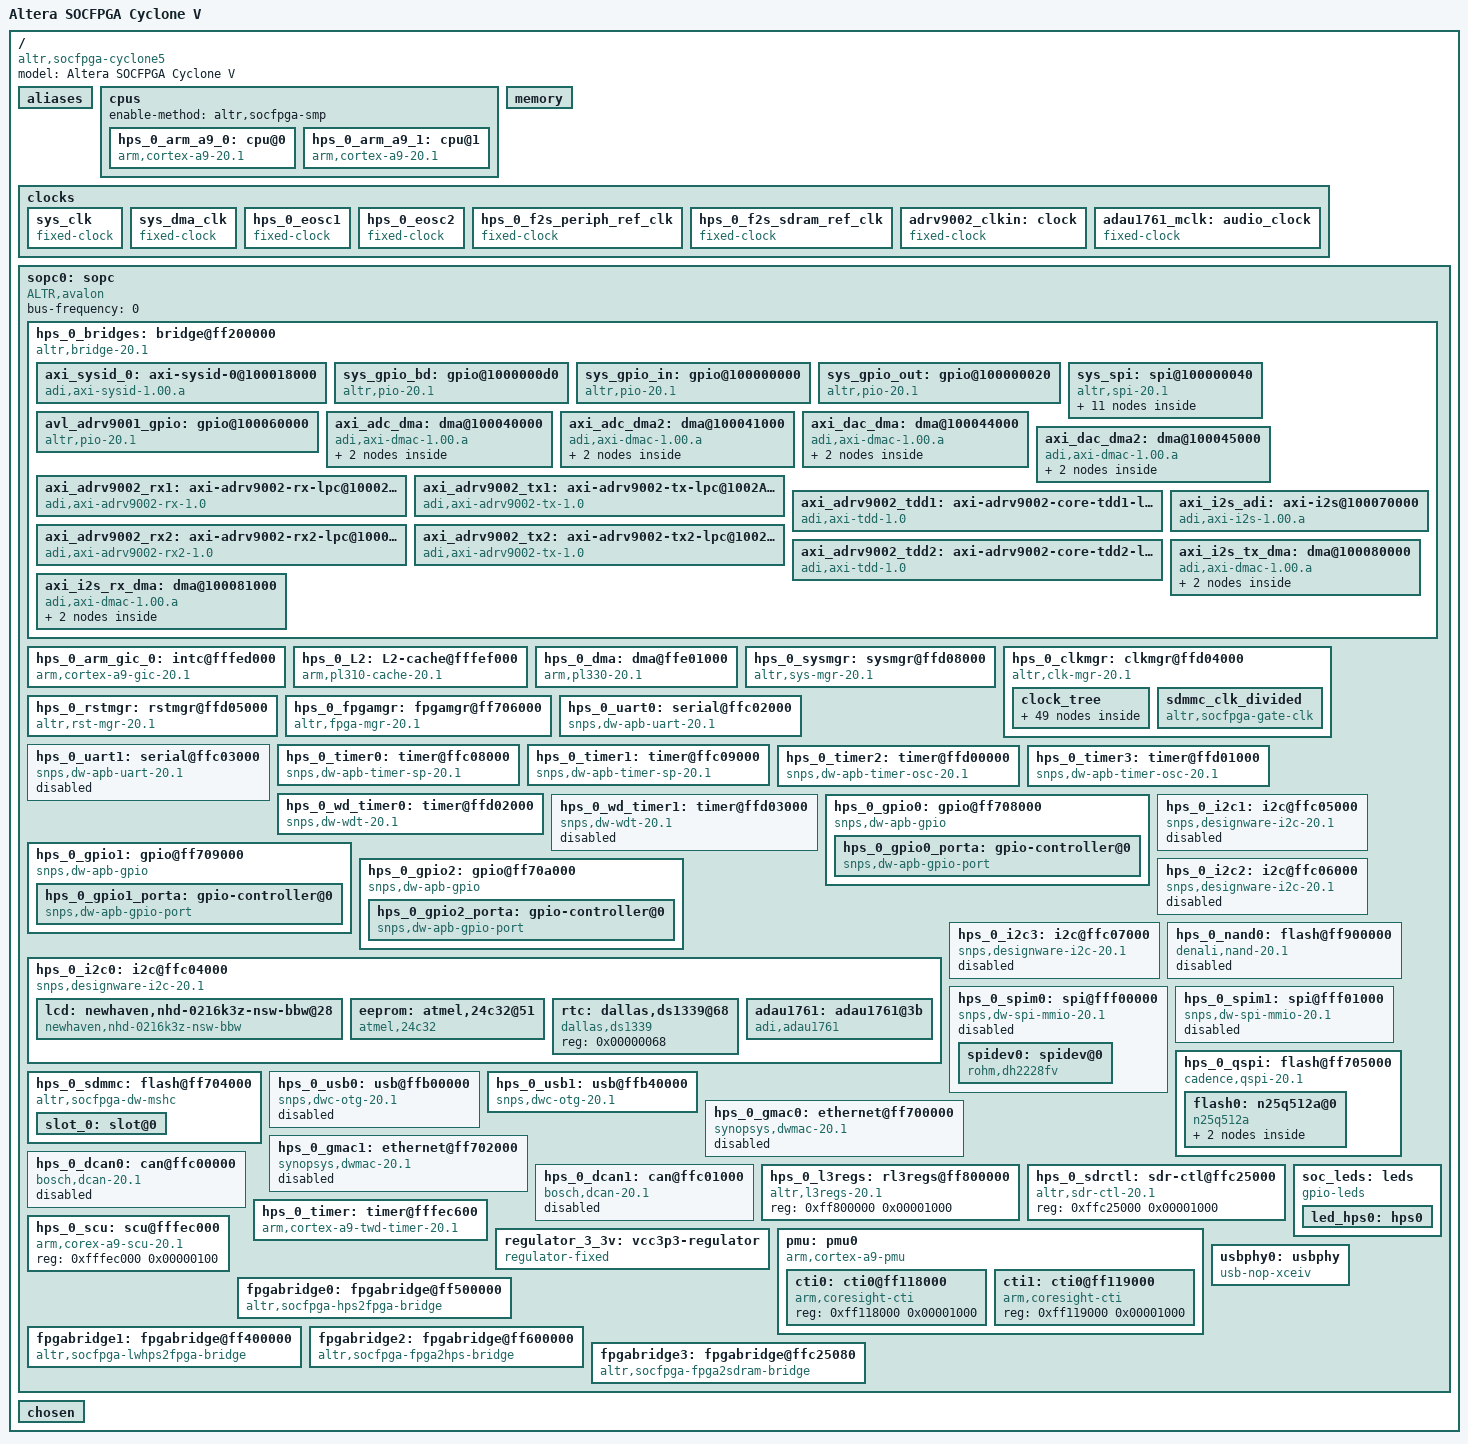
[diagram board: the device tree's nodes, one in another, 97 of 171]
/*
 * This devicetree is generated by sopc2dts version 20.1 [9b3346002ac555f36b80b1bc56dad1cb86298234] on Fri Sep 02 09:02:25 JST 2022
 * Sopc2dts is written by Walter Goossens <waltergoossens@home.nl>
 * in cooperation with the nios2 community <nios2-dev@lists.rocketboards.org>
 */
/dts-v1/;

/ {
	model = "Altera SOCFPGA Cyclone V";	/* appended from boardinfo */
	compatible = "altr,socfpga-cyclone5", "altr,socfpga";	/* appended from boardinfo */
	#address-cells = <1>;
	#size-cells = <1>;

	aliases {
		ethernet0 = "/sopc/ethernet@ff702000";
		serial0 = &hps_0_uart0;
		serial1 = &hps_0_uart1;
	}; //end aliases

	cpus {
		#address-cells = <1>;
		#size-cells = <0>;
		enable-method = "altr,socfpga-smp";	/* appended from boardinfo */

		hps_0_arm_a9_0: cpu@0 {
			device_type = "cpu";
			compatible = "arm,cortex-a9-20.1", "arm,cortex-a9";
			reg = <0x00000000>;
			next-level-cache = <&hps_0_L2>;	/* appended from boardinfo */
		}; //end cpu@0 (hps_0_arm_a9_0)

		hps_0_arm_a9_1: cpu@1 {
			device_type = "cpu";
			compatible = "arm,cortex-a9-20.1", "arm,cortex-a9";
			reg = <0x00000001>;
			next-level-cache = <&hps_0_L2>;	/* appended from boardinfo */
		}; //end cpu@1 (hps_0_arm_a9_1)
	}; //end cpus

	memory {
		device_type = "memory";
		reg = <0xffff0000 0x00010000>,
			<0x00000000 0x80000000>;
	}; //end memory

	clocks {
		#address-cells = <1>;
		#size-cells = <1>;

		sys_clk: sys_clk {
			compatible = "fixed-clock";
			#clock-cells = <0>;
			clock-frequency = <50000000>;	/* 50.00 MHz */
			clock-output-names = "sys_clk-clk";
		}; //end sys_clk (sys_clk)

		sys_dma_clk: sys_dma_clk {
			compatible = "fixed-clock";
			#clock-cells = <0>;
			clock-frequency = <80000000>;	/* 80.00 MHz */
			clock-output-names = "sys_dma_clk-clk";
		}; //end sys_dma_clk (sys_dma_clk)

		hps_0_eosc1: hps_0_eosc1 {
			compatible = "fixed-clock";
			#clock-cells = <0>;
			clock-frequency = <25000000>;	/* 25.00 MHz */
			clock-output-names = "hps_0_eosc1-clk";
		}; //end hps_0_eosc1 (hps_0_eosc1)

		hps_0_eosc2: hps_0_eosc2 {
			compatible = "fixed-clock";
			#clock-cells = <0>;
			clock-frequency = <25000000>;	/* 25.00 MHz */
			clock-output-names = "hps_0_eosc2-clk";
		}; //end hps_0_eosc2 (hps_0_eosc2)

		hps_0_f2s_periph_ref_clk: hps_0_f2s_periph_ref_clk {
			compatible = "fixed-clock";
			#clock-cells = <0>;
			clock-frequency = <0>;	/* 0.00 Hz */
			clock-output-names = "hps_0_f2s_periph_ref_clk-clk";
		}; //end hps_0_f2s_periph_ref_clk (hps_0_f2s_periph_ref_clk)

		hps_0_f2s_sdram_ref_clk: hps_0_f2s_sdram_ref_clk {
			compatible = "fixed-clock";
			#clock-cells = <0>;
			clock-frequency = <0>;	/* 0.00 Hz */
			clock-output-names = "hps_0_f2s_sdram_ref_clk-clk";
		}; //end hps_0_f2s_sdram_ref_clk (hps_0_f2s_sdram_ref_clk)

		adrv9002_clkin: clock {
			compatible = "fixed-clock";
			clock-frequency = <49152000>;
			clock-output-names = "adrv9002_ext_refclk";
			#clock-cells = <0>;
		};

		adau1761_mclk: audio_clock {
			compatible = "fixed-clock";
			#clock-cells=<0>;
			clock-frequency = <12288000>;
			clock-output-names = "adau1761_mclk";
		};
	}; //end clocks

	sopc0: sopc {
		device_type = "soc";
		ranges;
		#address-cells = <1>;
		#size-cells = <1>;
		compatible = "ALTR,avalon", "simple-bus";
		bus-frequency = <0>;

		hps_0_bridges: bridge@ff200000 {
			compatible = "altr,bridge-20.1", "simple-bus";
			reg = <0xff200000 0x00200000>;
			clocks = <&sys_clk &sys_dma_clk>;
			clock-names = "h2f_lw_axi_clock", "f2h_sdram0_clock";
			#address-cells = <2>;
			#size-cells = <1>;
			ranges = <0x00000001 0x000000d0 0xff2000d0 0x00000010>,
				<0x00000001 0x00000000 0xff200000 0x00000010>,
				<0x00000001 0x00000020 0xff200020 0x00000010>,
				<0x00000001 0x00060000 0xff260000 0x00000010>,
				<0x00000001 0x00020000 0xff220000 0x00010000>,
				<0x00000001 0x00040000 0xff240000 0x00000800>,
				<0x00000001 0x00044000 0xff244000 0x00000800>,
				<0x00000001 0x00018000 0xff218000 0x00008000>,
				<0x00000001 0x00041000 0xff241000 0x00000800>,
				<0x00000001 0x00045000 0xff245000 0x00000800>,
				<0x00000001 0x00070000 0xff270000 0x00010000>,
				<0x00000001 0x00080000 0xff280000 0x00000800>,
				<0x00000001 0x00081000 0xff281000 0x00000800>,
				<0x00000001 0x00000040 0xff200040 0x00000020>;

			axi_sysid_0: axi-sysid-0@100018000 {
				compatible = "adi,axi-sysid-1.00.a";
				reg = <0x00000001 0x00018000 0x00008000>;
				clocks = <&sys_clk>;
			}; //end axi-sysid-0@100018000 (axi_sysid_0)

			sys_gpio_bd: gpio@1000000d0 {
				compatible = "altr,pio-20.1", "altr,pio-1.0";
				reg = <0x00000001 0x000000d0 0x00000010>;
				interrupt-parent = <&hps_0_arm_gic_0>;
				interrupts = <0 48 4>;
				clocks = <&sys_clk>;
				altr,gpio-bank-width = <32>;	/* embeddedsw.dts.params.altr,gpio-bank-width type NUMBER */
				altr,interrupt-type = <4>;	/* embeddedsw.dts.params.altr,interrupt-type type NUMBER */
				altr,interrupt_type = <4>;	/* embeddedsw.dts.params.altr,interrupt_type type NUMBER */
				level_trigger = <1>;	/* embeddedsw.dts.params.level_trigger type NUMBER */
				resetvalue = <0>;	/* embeddedsw.dts.params.resetvalue type NUMBER */
				#gpio-cells = <2>;
				gpio-controller;
			}; //end gpio@1000000d0 (sys_gpio_bd)

			sys_gpio_in: gpio@100000000 {
				compatible = "altr,pio-20.1", "altr,pio-1.0";
				reg = <0x00000001 0x00000000 0x00000010>;
				interrupt-parent = <&hps_0_arm_gic_0>;
				interrupts = <0 49 4>;
				clocks = <&sys_clk>;
				altr,gpio-bank-width = <32>;	/* embeddedsw.dts.params.altr,gpio-bank-width type NUMBER */
				altr,interrupt-type = <4>;	/* embeddedsw.dts.params.altr,interrupt-type type NUMBER */
				altr,interrupt_type = <4>;	/* embeddedsw.dts.params.altr,interrupt_type type NUMBER */
				level_trigger = <1>;	/* embeddedsw.dts.params.level_trigger type NUMBER */
				resetvalue = <0>;	/* embeddedsw.dts.params.resetvalue type NUMBER */
				#gpio-cells = <2>;
				gpio-controller;
			}; //end gpio@100000000 (sys_gpio_in)

			sys_gpio_out: gpio@100000020 {
				compatible = "altr,pio-20.1", "altr,pio-1.0";
				reg = <0x00000001 0x00000020 0x00000010>;
				clocks = <&sys_clk>;
				altr,gpio-bank-width = <32>;	/* embeddedsw.dts.params.altr,gpio-bank-width type NUMBER */
				resetvalue = <0>;	/* embeddedsw.dts.params.resetvalue type NUMBER */
				#gpio-cells = <2>;
				gpio-controller;
			}; //end gpio@100000020 (sys_gpio_out)

			sys_spi: spi@100000040 {
				compatible = "altr,spi-20.1", "altr,spi-1.0";
				reg = <0x00000001 0x00000040 0x00000020>;
				interrupt-parent = <&hps_0_arm_gic_0>;
				interrupts = <0 46 4>;
				clocks = <&sys_clk>;
				#address-cells = <1>;
				#size-cells = <0>;
				bus-num = <0>;
				num-chipselect = <1>;
				status = "okay";

				adc0_adrv9002: adrv9002-phy@0 {
					compatible = "adi,adrv9002";
					reg = <0x0>;
					spi-max-frequency = <10000000>;
					clocks = <&adrv9002_clkin 0x0>;
					clock-names = "adrv9002_ext_refclk";
					clock-output-names = "rx1_sampl_clk", "tx1_sampl_clk", "tdd1_intf_clk", "rx2_sampl_clk", "tx2_sampl_clk", "tdd2_intf_clk";
					#clock-cells = <0x1>;
					interrupt-parent = <&avl_adrv9001_gpio>;
					reset-gpios = <&avl_adrv9001_gpio 14 1>;
					ssi-sync-gpios = <&avl_adrv9001_gpio 20 0>;

					adi,channels {
						#address-cells = <1>;
						#size-cells = <0>;

						rx0: rx@0 {
							reg = <0>;
							adi,port = <0>;
							orx-gpios = <&avl_adrv9001_gpio 0 0>; /* dgpio0 */
						};

						rx1: rx@1 {
							reg = <1>;
							adi,port = <0>;
							orx-gpios = <&avl_adrv9001_gpio 1 0>; /* dgpio1 */
						};

						tx0: tx@0 {
							reg = <0>;
							adi,port = <1>;
						};

						tx1: tx@1 {
							reg = <1>;
							adi,port = <1>;
						};

					};

					adi,gpios {
						#address-cells = <1>;
						#size-cells = <0>;

						gpio@0 {
							reg = <1>;
							adi,signal = <0>; /* ADI_ADRV9001_GPIO_SIGNAL_ORX_ENABLE_1 */
						};

						gpio@1 {
							reg = <2>;
							adi,signal = <1>; /* ADI_ADRV9001_GPIO_SIGNAL_ORX_ENABLE_2 */
						};
					};

					adi,frequency-hopping {
						adi,fh-mode = <0x3>;
						adi-fh-rx-zero-if-en;

						adi,fh-hop-signal-2 {
							adi,fh-hop-rx-ports = <0x1>;
							adi,fh-hop-tx-ports = <0x1>;
						};
					};
				};
			}; //end spi@100000040 (sys_spi)

			avl_adrv9001_gpio: gpio@100060000 {
				compatible = "altr,pio-20.1", "altr,pio-1.0";
				reg = <0x00000001 0x00060000 0x00000010>;
				interrupt-parent = <&hps_0_arm_gic_0>;
				interrupts = <0 47 4>;
				clocks = <&sys_clk>;
				altr,gpio-bank-width = <19>;	/* embeddedsw.dts.params.altr,gpio-bank-width type NUMBER */
				altr,interrupt-type = <4>;	/* embeddedsw.dts.params.altr,interrupt-type type NUMBER */
				altr,interrupt_type = <4>;	/* embeddedsw.dts.params.altr,interrupt_type type NUMBER */
				level_trigger = <1>;	/* embeddedsw.dts.params.level_trigger type NUMBER */
				resetvalue = <0>;	/* embeddedsw.dts.params.resetvalue type NUMBER */
				#gpio-cells = <2>;
				gpio-controller;
			}; //end gpio@100060000 (avl_adrv9001_gpio)

			axi_adc_dma: dma@100040000 {
				compatible = "adi,axi-dmac-1.00.a";
				reg = <0x00000001 0x00040000 0x00000800>;
				#dma-cells = <0x1>;
				interrupt-parent = <&hps_0_arm_gic_0>;
				interrupts = <0 40 4>;
				clocks = <&sys_clk &sys_dma_clk &sys_dma_clk>;
				clock-names = "s_axi_clock", "m_dest_axi_clock", "if_fifo_wr_clk";
				adi,channels {
					#size-cells = <0>;
					#address-cells = <1>;

					dma-channel@0 {
						reg = <0>;
						adi,source-bus-width = <64>;
						adi,source-bus-type = <2>;
						adi,destination-bus-width = <64>;
						adi,destination-bus-type = <0>;
					};
				};
			}; //end dma@100040000 (axi_adc_dma)

			axi_adc_dma2: dma@100041000 {
				compatible = "adi,axi-dmac-1.00.a";
				reg = <0x00000001 0x00041000 0x00000800>;
				#dma-cells = <0x1>;
				interrupt-parent = <&hps_0_arm_gic_0>;
				interrupts = <0 41 4>;
				clocks = <&sys_clk &sys_dma_clk &sys_dma_clk>;
				clock-names = "s_axi_clock", "m_dest_axi_clock", "if_fifo_wr_clk";
				adi,channels {
					#size-cells = <0>;
					#address-cells = <1>;

					dma-channel@0 {
						reg = <0>;
						adi,source-bus-width = <64>;
						adi,source-bus-type = <2>;
						adi,destination-bus-width = <64>;
						adi,destination-bus-type = <0>;
					};
				};
			}; //end dma@100041000 (axi_adc_dma2)

			axi_dac_dma: dma@100044000 {
				compatible = "adi,axi-dmac-1.00.a";
				reg = <0x00000001 0x00044000 0x00000800>;
				#dma-cells = <0x1>;
				interrupt-parent = <&hps_0_arm_gic_0>;
				interrupts = <0 42 4>;
				clocks = <&sys_clk &sys_dma_clk &sys_dma_clk>;
				clock-names = "s_axi_clock", "m_src_axi_clock", "if_m_axis_aclk";
				adi,channels {
					#size-cells = <0>;
					#address-cells = <1>;
					dma-channel@0 {
						reg = <0>;
						adi,source-bus-width = <64>;
						adi,source-bus-type = <0>;
						adi,destination-bus-width = <64>;
						adi,destination-bus-type = <2>;
					};
				};
			}; //end dma@100044000 (axi_dac_dma)

			axi_dac_dma2: dma@100045000 {
				compatible = "adi,axi-dmac-1.00.a";
				reg = <0x00000001 0x00045000 0x00000800>;
				#dma-cells = <0x1>;
				interrupt-parent = <&hps_0_arm_gic_0>;
				interrupts = <0 43 4>;
				clocks = <&sys_clk &sys_dma_clk &sys_dma_clk>;
				clock-names = "s_axi_clock", "m_src_axi_clock", "if_m_axis_aclk";
				adi,channels {
					#size-cells = <0>;
					#address-cells = <1>;
					dma-channel@0 {
						reg = <0>;
						adi,source-bus-width = <64>;
						adi,source-bus-type = <0>;
						adi,destination-bus-width = <64>;
						adi,destination-bus-type = <2>;
					};
				};
			}; //end dma@100045000 (axi_dac_dma2)

			axi_adrv9002_rx1: axi-adrv9002-rx-lpc@100020000 {
				compatible = "adi,axi-adrv9002-rx-1.0";
				reg = <0x00000001 0x00020000 0x00006000>;
				clocks = <&adc0_adrv9002 0>;
				dmas = <&axi_adc_dma 0>;
				dma-names = "rx";
				spibus-connected = <&adc0_adrv9002>;
			}; //end axi-adrv9002-rx-lpc@100020000 (axi_adrv9002_rx1)

			axi_adrv9002_tx1: axi-adrv9002-tx-lpc@1002A000 {
				compatible = "adi,axi-adrv9002-tx-1.0";
				reg = <0x00000001 0x0002A000 0x00002000>;
				clocks = <&adc0_adrv9002 1>;
				clock-names = "sampl_clk";
				dmas = <&axi_dac_dma 0>;
				dma-names = "tx";
				adi,axi-dds-default-scale = <0x800>;
				adi,axi-dds-default-frequency = <2000000>;
			}; //end axi-adrv9002-tx-lpc@1003A000 (axi_adrv9002_tx1)

			axi_adrv9002_tdd1: axi-adrv9002-core-tdd1-lpc@1002C800 {
				compatible = "adi,axi-tdd-1.0";
				reg = <0x00000001 0x0002C800 0x00000400>;
				clocks = <&sys_dma_clk>, <&adc0_adrv9002 2>;
				clock-names = "s_axi_aclk", "intf_clk";
				label = "axi-core-tdd-1";
			}; //end axi-adrv9002-core-tdd1-lpc@1002C800 (axi_adrv9002_tdd1)

			axi_adrv9002_rx2: axi-adrv9002-rx2-lpc@100029000 {
				compatible = "adi,axi-adrv9002-rx2-1.0";
				reg = <0x00000001 0x00029000 0x00001000>;
				clocks = <&adc0_adrv9002 3>;
				clock-names = "sampl_clk";
				dmas = <&axi_adc_dma2 0>;
				dma-names = "rx";
			}; //end axi-adrv9002-rx-lpc@100029000 (axi_adrv9002_rx2)

			axi_adrv9002_tx2: axi-adrv9002-tx2-lpc@1002C000 {
				compatible = "adi,axi-adrv9002-tx-1.0";
				reg = <0x00000001 0x0002C000 0x00002000>;
				clocks = <&adc0_adrv9002 4>;
				clock-names = "sampl_clk";
				dmas = <&axi_dac_dma2 0>;
				dma-names = "tx";
				adi,axi-dds-default-scale = <0x800>;
				adi,axi-dds-default-frequency = <2000000>;
			}; //end axi-adrv9002-tx2-lpc@1002C000 (axi_adrv9002_tx2)

			axi_adrv9002_tdd2: axi-adrv9002-core-tdd2-lpc@1002CC00 {
				compatible = "adi,axi-tdd-1.0";
				reg = <0x00000001 0x0002CC00 0x00000400>;
				clocks = <&sys_dma_clk>, <&adc0_adrv9002 5>;
				clock-names = "s_axi_aclk", "intf_clk";
				label = "axi-core-tdd-2";
			}; //end axi-adrv9002-core-tdd2-lpc@1002CC00 (axi_adrv9002_tdd2)

			axi_i2s_adi: axi-i2s@100070000 {
				compatible = "adi,axi-i2s-1.00.a";
				reg = <0x00000001 0x00070000 0x00010000>;
				clocks = <&sys_clk &adau1761_mclk>; // clocks = <&sys_clk &sys_clk &sys_clk>;
				clock-names = "axi", "ref"; // clock-names = "s_axi_clock", "if_m_axis_aclk", "if_s_axis_aclk";
				dmas = <&axi_i2s_tx_dma 0 &axi_i2s_rx_dma 0>; // dmas = <&axi_i2s_tx_dma 0 &axi_i2s_rx_dma 1>;
				dma-names = "tx", "rx"; 
			}; //end axi-i2s@100070000 (axi_i2s_adi)

			axi_i2s_tx_dma: dma@100080000 {
				compatible = "adi,axi-dmac-1.00.a";
				reg = <0x00000001 0x00080000 0x00000800>;
				#dma-cells = <0x1>; // #dma-cells = <0x2>;
				interrupt-parent = <&hps_0_arm_gic_0>;
				interrupts = <0 44 4>;
				clocks = <&sys_clk &sys_clk &sys_clk>;
				clock-names = "s_axi_clock", "m_src_axi_clock", "if_m_axis_aclk";
				adi,channels {
					#size-cells = <0>;
					#address-cells = <1>;
					dma-channel@0 {
						reg = <0>;
						adi,source-bus-width = <64>;
						adi,source-bus-type = <0>;
						adi,destination-bus-width = <32>;
						adi,destination-bus-type = <1>;
					};
				};
			}; //end dma@100080000 (axi_i2s_tx_dma)

			axi_i2s_rx_dma: dma@100081000 {
				compatible = "adi,axi-dmac-1.00.a";
				reg = <0x00000001 0x00081000 0x00000800>;
				#dma-cells = <0x1>; // #dma-cells = <0x3>;
				interrupt-parent = <&hps_0_arm_gic_0>;
				interrupts = <0 45 4>;
				clocks = <&sys_clk &sys_clk &sys_clk>;
				clock-names = "s_axi_clock", "m_dest_axi_clock", "if_s_axis_aclk";
				adi,channels {
					#size-cells = <0>;
					#address-cells = <1>;
					dma-channel@0 {
						reg = <0>;
						adi,source-bus-width = <32>;
						adi,source-bus-type = <1>;
						adi,destination-bus-width = <64>;
						adi,destination-bus-type = <0>;
					};
				};
			}; //end dma@100081000 (axi_i2s_rx_dma)

		}; //end bridge@ff200000 (hps_0_bridges)

		hps_0_arm_gic_0: intc@fffed000 {
			compatible = "arm,cortex-a9-gic-20.1", "arm,cortex-a9-gic";
			reg = <0xfffed000 0x00001000>,
				<0xfffec100 0x00000100>;
			reg-names = "axi_slave0", "axi_slave1";
			interrupt-controller;
			#interrupt-cells = <3>;
		}; //end intc@fffed000 (hps_0_arm_gic_0)

		hps_0_L2: L2-cache@fffef000 {
			compatible = "arm,pl310-cache-20.1", "arm,pl310-cache";
			reg = <0xfffef000 0x00001000>;
			interrupt-parent = <&hps_0_arm_gic_0>;
			interrupts = <0 38 4>;
			cache-level = <2>;	/* embeddedsw.dts.params.cache-level type NUMBER */
			cache-unified;	/* appended from boardinfo */
			arm,tag-latency = <1 1 1>;	/* appended from boardinfo */
			arm,data-latency = <2 1 1>;	/* appended from boardinfo */
		}; //end L2-cache@fffef000 (hps_0_L2)

		hps_0_dma: dma@ffe01000 {
			compatible = "arm,pl330-20.1", "arm,pl330", "arm,primecell";
			reg = <0xffe01000 0x00001000>;
			interrupt-parent = <&hps_0_arm_gic_0>;
			interrupts = <0 104 4>;
			clocks = <&l4_main_clk>;
			#dma-cells = <1>;	/* embeddedsw.dts.params.#dma-cells type NUMBER */
			#dma-channels = <8>;	/* embeddedsw.dts.params.#dma-channels type NUMBER */
			#dma-requests = <32>;	/* embeddedsw.dts.params.#dma-requests type NUMBER */
			clock-names = "apb_pclk";	/* embeddedsw.dts.params.clock-names type STRING */
			copy-align = <3>;	/* embeddedsw.dts.params.copy-align type NUMBER */
			nr-irqs = <9>;	/* embeddedsw.dts.params.nr-irqs type NUMBER */
			nr-valid-peri = <9>;	/* embeddedsw.dts.params.nr-valid-peri type NUMBER */
		}; //end dma@ffe01000 (hps_0_dma)

		hps_0_sysmgr: sysmgr@ffd08000 {
			compatible = "altr,sys-mgr-20.1", "altr,sys-mgr", "syscon";
			reg = <0xffd08000 0x00000400>;
			cpu1-start-addr = <4291854532>;	/* embeddedsw.dts.params.cpu1-start-addr type NUMBER */
		}; //end sysmgr@ffd08000 (hps_0_sysmgr)

		hps_0_clkmgr: clkmgr@ffd04000 {
			compatible = "altr,clk-mgr-20.1", "altr,clk-mgr";
			reg = <0xffd04000 0x00001000>;
			clocks = <&hps_0_eosc1 &hps_0_eosc2 &hps_0_f2s_periph_ref_clk &hps_0_f2s_sdram_ref_clk>;
			clock-names = "eosc1", "eosc2", "f2s_periph_ref_clk", "f2s_sdram_ref_clk";

			clock_tree {
				#size-cells = <0>;
				#address-cells = <1>;

				sdram_pll: sdram_pll@c0 {
					compatible = "altr,socfpga-pll-clock";
					reg = <0x000000c0>;
					clocks = <&hps_0_eosc1 &hps_0_eosc2 &hps_0_f2s_sdram_ref_clk>;
					clock-names = "hps_0_eosc1", "hps_0_eosc2", "hps_0_f2s_sdram_ref_clk";
					#clock-cells = <0>;
					#address-cells = <1>;
					#size-cells = <0>;

					ddr_dqs_clk: ddr_dqs_clk@c8 {
						compatible = "altr,socfpga-perip-clk";
						reg = <0x000000c8>;
						clocks = <&sdram_pll>;
						#clock-cells = <0>;
					}; //end ddr_dqs_clk (ddr_dqs_clk)

					ddr_2x_dqs_clk: ddr_2x_dqs_clk@cc {
						compatible = "altr,socfpga-perip-clk";
						reg = <0x000000cc>;
						clocks = <&sdram_pll>;
						#clock-cells = <0>;
					}; //end ddr_2x_dqs_clk (ddr_2x_dqs_clk)

					ddr_dq_clk: ddr_dq_clk@d0 {
						compatible = "altr,socfpga-perip-clk";
						reg = <0x000000d0>;
						clocks = <&sdram_pll>;
						#clock-cells = <0>;
					}; //end ddr_dq_clk (ddr_dq_clk)

					s2f_usr2_clk: s2f_usr2_clk@d4 {
						compatible = "altr,socfpga-perip-clk";
						reg = <0x000000d4>;
						clocks = <&sdram_pll>;
						#clock-cells = <0>;
					}; //end s2f_usr2_clk (s2f_usr2_clk)
				}; //end sdram_pll (sdram_pll)

				periph_pll: periph_pll@80 {
					compatible = "altr,socfpga-pll-clock";
					reg = <0x00000080>;
					clocks = <&hps_0_eosc1 &hps_0_eosc2 &hps_0_f2s_periph_ref_clk>;
					clock-names = "hps_0_eosc1", "hps_0_eosc2", "hps_0_f2s_periph_ref_clk";
					#clock-cells = <0>;
					#address-cells = <1>;
					#size-cells = <0>;

					per_nand_mmc_clk: per_nand_mmc_clk@94 {
						compatible = "altr,socfpga-perip-clk";
						reg = <0x00000094>;
						clocks = <&periph_pll>;
						#clock-cells = <0>;
					}; //end per_nand_mmc_clk (per_nand_mmc_clk)

					per_base_clk: per_base_clk@98 {
						compatible = "altr,socfpga-perip-clk";
						reg = <0x00000098>;
						clocks = <&periph_pll>;
						#clock-cells = <0>;
					}; //end per_base_clk (per_base_clk)

					per_qspi_clk: per_qspi_clk@90 {
						compatible = "altr,socfpga-perip-clk";
						reg = <0x00000090>;
						clocks = <&periph_pll>;
						#clock-cells = <0>;
					}; //end per_qspi_clk (per_qspi_clk)

					s2f_usr1_clk: s2f_usr1_clk@9c {
						compatible = "altr,socfpga-perip-clk";
						reg = <0x0000009c>;
						clocks = <&periph_pll>;
						#clock-cells = <0>;
					}; //end s2f_usr1_clk (s2f_usr1_clk)

					emac0_clk: emac0_clk@88 {
						compatible = "altr,socfpga-perip-clk";
						reg = <0x00000088>;
						clocks = <&periph_pll>;
						#clock-cells = <0>;
					}; //end emac0_clk (emac0_clk)

					emac1_clk: emac1_clk@8c {
						compatible = "altr,socfpga-perip-clk";
						reg = <0x0000008c>;
						clocks = <&periph_pll>;
						#clock-cells = <0>;
					}; //end emac1_clk (emac1_clk)
				}; //end periph_pll (periph_pll)

				main_pll: main_pll@40 {
					compatible = "altr,socfpga-pll-clock";
					reg = <0x00000040>;
					clocks = <&hps_0_eosc1>;
					#clock-cells = <0>;
					#address-cells = <1>;
					#size-cells = <0>;

					cfg_s2f_usr0_clk: cfg_s2f_usr0_clk@5c {
						compatible = "altr,socfpga-perip-clk";
						reg = <0x0000005c>;
						clocks = <&main_pll>;
						#clock-cells = <0>;
					}; //end cfg_s2f_usr0_clk (cfg_s2f_usr0_clk)

					main_qspi_clk: main_qspi_clk@54 {
						compatible = "altr,socfpga-perip-clk";
						reg = <0x00000054>;
						clocks = <&main_pll>;
						#clock-cells = <0>;
					}; //end main_qspi_clk (main_qspi_clk)

					dbg_base_clk: dbg_base_clk@50 {
						compatible = "altr,socfpga-perip-clk";
						reg = <0x00000050>;
						clocks = <&main_pll &hps_0_eosc1>;
						clock-names = "main_pll", "hps_0_eosc1";
						#clock-cells = <0>;
						div-reg = <0x000000e8 0x00000000 0x00000009>;
					}; //end dbg_base_clk (dbg_base_clk)

					mpuclk: mpuclk@48 {
						compatible = "altr,socfpga-perip-clk";
						reg = <0x00000048>;
						clocks = <&main_pll>;
						#clock-cells = <0>;
						div-reg = <0x000000e0 0x00000000 0x00000009>;
					}; //end mpuclk (mpuclk)

					mainclk: mainclk@4c {
						compatible = "altr,socfpga-perip-clk";
						reg = <0x0000004c>;
						clocks = <&main_pll>;
						#clock-cells = <0>;
						div-reg = <0x000000e4 0x00000000 0x00000009>;
					}; //end mainclk (mainclk)

					main_nand_sdmmc_clk: main_nand_sdmmc_clk@58 {
						compatible = "altr,socfpga-perip-clk";
						reg = <0x00000058>;
						clocks = <&main_pll>;
						#clock-cells = <0>;
					}; //end main_nand_sdmmc_clk (main_nand_sdmmc_clk)
				}; //end main_pll (main_pll)

				mpu_l2_ram_clk: mpu_l2_ram_clk {
					compatible = "altr,socfpga-gate-clk";
					clocks = <&mpuclk>;
					#clock-cells = <0>;
					fixed-divider = <2>;
				}; //end mpu_l2_ram_clk (mpu_l2_ram_clk)

				l4_main_clk: l4_main_clk {
					compatible = "altr,socfpga-gate-clk";
					clocks = <&mainclk>;
					#clock-cells = <0>;
					clk-gate = <0x00000060 0x00000000>;
				}; //end l4_main_clk (l4_main_clk)

				l3_mp_clk: l3_mp_clk {
					compatible = "altr,socfpga-gate-clk";
					clocks = <&mainclk>;
					#clock-cells = <0>;
					clk-gate = <0x00000060 0x00000001>;
					div-reg = <0x00000064 0x00000000 0x00000002>;
				}; //end l3_mp_clk (l3_mp_clk)

				l3_sp_clk: l3_sp_clk {
					compatible = "altr,socfpga-gate-clk";
					clocks = <&l3_mp_clk>;
					#clock-cells = <0>;
					div-reg = <0x00000064 0x00000002 0x00000002>;
				}; //end l3_sp_clk (l3_sp_clk)

				l4_mp_clk: l4_mp_clk {
					compatible = "altr,socfpga-gate-clk";
					clocks = <&mainclk &per_base_clk>;
					clock-names = "mainclk", "per_base_clk";
					#clock-cells = <0>;
					clk-gate = <0x00000060 0x00000002>;
					div-reg = <0x00000064 0x00000004 0x00000003>;
				}; //end l4_mp_clk (l4_mp_clk)

				l4_sp_clk: l4_sp_clk {
					compatible = "altr,socfpga-gate-clk";
					clocks = <&mainclk &per_base_clk>;
					clock-names = "mainclk", "per_base_clk";
					#clock-cells = <0>;
					clk-gate = <0x00000060 0x00000003>;
					div-reg = <0x00000064 0x00000007 0x00000003>;
				}; //end l4_sp_clk (l4_sp_clk)

				dbg_at_clk: dbg_at_clk {
					compatible = "altr,socfpga-gate-clk";
					clocks = <&dbg_base_clk>;
					#clock-cells = <0>;
					clk-gate = <0x00000060 0x00000004>;
					div-reg = <0x00000068 0x00000000 0x00000002>;
				}; //end dbg_at_clk (dbg_at_clk)

				dbg_clk: dbg_clk {
					compatible = "altr,socfpga-gate-clk";
					clocks = <&dbg_at_clk>;
					#clock-cells = <0>;
					clk-gate = <0x00000060 0x00000005>;
					div-reg = <0x00000068 0x00000002 0x00000002>;
				}; //end dbg_clk (dbg_clk)

				dbg_trace_clk: dbg_trace_clk {
					compatible = "altr,socfpga-gate-clk";
					clocks = <&dbg_base_clk>;
					#clock-cells = <0>;
					clk-gate = <0x00000060 0x00000006>;
					div-reg = <0x0000006c 0x00000000 0x00000003>;
				}; //end dbg_trace_clk (dbg_trace_clk)

				dbg_timer_clk: dbg_timer_clk {
					compatible = "altr,socfpga-gate-clk";
					clocks = <&dbg_base_clk>;
					#clock-cells = <0>;
					clk-gate = <0x00000060 0x00000007>;
				}; //end dbg_timer_clk (dbg_timer_clk)

				cfg_clk: cfg_clk {
					compatible = "altr,socfpga-gate-clk";
					clocks = <&cfg_s2f_usr0_clk>;
					#clock-cells = <0>;
					clk-gate = <0x00000060 0x00000008>;
				}; //end cfg_clk (cfg_clk)

				h2f_user0_clock: h2f_user0_clock {
					compatible = "altr,socfpga-gate-clk";
					clocks = <&cfg_s2f_usr0_clk>;
					#clock-cells = <0>;
					clk-gate = <0x00000060 0x00000009>;
				}; //end h2f_user0_clock (h2f_user0_clock)

				emac_0_clk: emac_0_clk {
					compatible = "altr,socfpga-gate-clk";
					clocks = <&emac0_clk>;
					#clock-cells = <0>;
					clk-gate = <0x000000a0 0x00000000>;
				}; //end emac_0_clk (emac_0_clk)

				emac_1_clk: emac_1_clk {
					compatible = "altr,socfpga-gate-clk";
					clocks = <&emac1_clk>;
					#clock-cells = <0>;
					clk-gate = <0x000000a0 0x00000001>;
				}; //end emac_1_clk (emac_1_clk)

				usb_mp_clk: usb_mp_clk {
					compatible = "altr,socfpga-gate-clk";
					clocks = <&per_base_clk>;
					#clock-cells = <0>;
					clk-gate = <0x000000a0 0x00000002>;
					div-reg = <0x000000a4 0x00000000 0x00000003>;
				}; //end usb_mp_clk (usb_mp_clk)

				spi_m_clk: spi_m_clk {
					compatible = "altr,socfpga-gate-clk";
					clocks = <&per_base_clk>;
					#clock-cells = <0>;
					clk-gate = <0x000000a0 0x00000003>;
					div-reg = <0x000000a4 0x00000003 0x00000003>;
				}; //end spi_m_clk (spi_m_clk)

				can0_clk: can0_clk {
					compatible = "altr,socfpga-gate-clk";
					clocks = <&per_base_clk>;
					#clock-cells = <0>;
					clk-gate = <0x000000a0 0x00000004>;
					div-reg = <0x000000a4 0x00000006 0x00000003>;
				}; //end can0_clk (can0_clk)

				can1_clk: can1_clk {
					compatible = "altr,socfpga-gate-clk";
					clocks = <&per_base_clk>;
					#clock-cells = <0>;
					clk-gate = <0x000000a0 0x00000005>;
					div-reg = <0x000000a4 0x00000009 0x00000003>;
				}; //end can1_clk (can1_clk)

				gpio_db_clk: gpio_db_clk {
					compatible = "altr,socfpga-gate-clk";
					clocks = <&per_base_clk>;
					#clock-cells = <0>;
					clk-gate = <0x000000a0 0x00000006>;
					div-reg = <0x000000a8 0x00000000 0x00000018>;
				}; //end gpio_db_clk (gpio_db_clk)

				h2f_user1_clock: h2f_user1_clock {
					compatible = "altr,socfpga-gate-clk";
					clocks = <&s2f_usr1_clk>;
					#clock-cells = <0>;
					clk-gate = <0x000000a0 0x00000007>;
				}; //end h2f_user1_clock (h2f_user1_clock)

				sdmmc_clk: sdmmc_clk {
					compatible = "altr,socfpga-gate-clk";
					clocks = <&hps_0_f2s_periph_ref_clk &main_nand_sdmmc_clk &per_nand_mmc_clk>;
					clock-names = "hps_0_f2s_periph_ref_clk", "main_nand_sdmmc_clk", "per_nand_mmc_clk";
					#clock-cells = <0>;
					clk-gate = <0x000000a0 0x00000008>;
					clk-phase = <0 135>;	/* appended from boardinfo */
				}; //end sdmmc_clk (sdmmc_clk)

				nand_x_clk: nand_x_clk {
					compatible = "altr,socfpga-gate-clk";
					clocks = <&hps_0_f2s_periph_ref_clk &main_nand_sdmmc_clk &per_nand_mmc_clk>;
					clock-names = "hps_0_f2s_periph_ref_clk", "main_nand_sdmmc_clk", "per_nand_mmc_clk";
					#clock-cells = <0>;
					clk-gate = <0x000000a0 0x00000009>;
				}; //end nand_x_clk (nand_x_clk)

				nand_clk: nand_clk {
					compatible = "altr,socfpga-gate-clk";
					clocks = <&hps_0_f2s_periph_ref_clk &main_nand_sdmmc_clk &per_nand_mmc_clk>;
					clock-names = "hps_0_f2s_periph_ref_clk", "main_nand_sdmmc_clk", "per_nand_mmc_clk";
					#clock-cells = <0>;
					clk-gate = <0x000000a0 0x0000000a>;
					fixed-divider = <4>;
				}; //end nand_clk (nand_clk)

				qspi_clk: qspi_clk {
					compatible = "altr,socfpga-gate-clk";
					clocks = <&hps_0_f2s_periph_ref_clk &main_qspi_clk &per_qspi_clk>;
					clock-names = "hps_0_f2s_periph_ref_clk", "main_qspi_clk", "per_qspi_clk";
					#clock-cells = <0>;
					clk-gate = <0x000000a0 0x0000000b>;
				}; //end qspi_clk (qspi_clk)

				ddr_dqs_clk_gate: ddr_dqs_clk_gate {
					compatible = "altr,socfpga-gate-clk";
					clocks = <&ddr_dqs_clk>;
					#clock-cells = <0>;
					clk-gate = <0x000000d8 0x00000000>;
				}; //end ddr_dqs_clk_gate (ddr_dqs_clk_gate)

				ddr_2x_dqs_clk_gate: ddr_2x_dqs_clk_gate {
					compatible = "altr,socfpga-gate-clk";
					clocks = <&ddr_2x_dqs_clk>;
					#clock-cells = <0>;
					clk-gate = <0x000000d8 0x00000001>;
				}; //end ddr_2x_dqs_clk_gate (ddr_2x_dqs_clk_gate)

				ddr_dq_clk_gate: ddr_dq_clk_gate {
					compatible = "altr,socfpga-gate-clk";
					clocks = <&ddr_dq_clk>;
					#clock-cells = <0>;
					clk-gate = <0x000000d8 0x00000002>;
				}; //end ddr_dq_clk_gate (ddr_dq_clk_gate)

				h2f_user2_clock: h2f_user2_clock {
					compatible = "altr,socfpga-gate-clk";
					clocks = <&s2f_usr2_clk>;
					#clock-cells = <0>;
					clk-gate = <0x000000d8 0x00000003>;
				}; //end h2f_user2_clock (h2f_user2_clock)

				l3_main_clk: l3_main_clk {
					compatible = "altr,socfpga-gate-clk";
					clocks = <&mainclk>;
					#clock-cells = <0>;
				}; //end l3_main_clk (l3_main_clk)

				mpu_periph_clk: mpu_periph_clk {
					compatible = "altr,socfpga-perip-clk";
					clocks = <&mpuclk>;
					#clock-cells = <0>;
					reg = <0x00000000>;
					fixed-divider = <4>;
				}; //end mpu_periph_clk (mpu_periph_clk)
			}; //end clock_tree

			sdmmc_clk_divided: sdmmc_clk_divided {
				#clock-cells = <0>;	/* appended from boardinfo */
				compatible = "altr,socfpga-gate-clk";	/* appended from boardinfo */
				clocks = <&sdmmc_clk>;	/* appended from boardinfo */
				clk-gate = <0x000000a0 0x00000008>;	/* appended from boardinfo */
				fixed-divider = <4>;	/* appended from boardinfo */
			}; //end sdmmc_clk_divided (sdmmc_clk_divided)
		}; //end clkmgr@ffd04000 (hps_0_clkmgr)

		hps_0_rstmgr: rstmgr@ffd05000 {
			compatible = "altr,rst-mgr-20.1", "altr,rst-mgr", "syscon";
			reg = <0xffd05000 0x00000100>;
			#reset-cells = <1>;	/* appended from boardinfo */
			altr,modrst-offset = <16>;	/* embeddedsw.dts.params.altr,modrst-offset type NUMBER */
		}; //end rstmgr@ffd05000 (hps_0_rstmgr)

		hps_0_fpgamgr: fpgamgr@ff706000 {
			compatible = "altr,fpga-mgr-20.1", "altr,fpga-mgr", "altr,socfpga-fpga-mgr";
			reg = <0xff706000 0x00001000>,
				<0xffb90000 0x00000100>;
			reg-names = "axi_slave0", "axi_slave1";
			interrupt-parent = <&hps_0_arm_gic_0>;
			interrupts = <0 175 4>;
			transport = "mmio";	/* embeddedsw.dts.params.transport type STRING */
			clocks = <&l4_mp_clk>;	/* appended from boardinfo */
		}; //end fpgamgr@ff706000 (hps_0_fpgamgr)

		hps_0_uart0: serial@ffc02000 {
			compatible = "snps,dw-apb-uart-20.1", "snps,dw-apb-uart";
			reg = <0xffc02000 0x00000100>;
			interrupt-parent = <&hps_0_arm_gic_0>;
			interrupts = <0 162 4>;
			clocks = <&l4_sp_clk>;
			reg-io-width = <4>;	/* embeddedsw.dts.params.reg-io-width type NUMBER */
			reg-shift = <2>;	/* embeddedsw.dts.params.reg-shift type NUMBER */
			status = "okay";	/* embeddedsw.dts.params.status type STRING */
		}; //end serial@ffc02000 (hps_0_uart0)

		hps_0_uart1: serial@ffc03000 {
			compatible = "snps,dw-apb-uart-20.1", "snps,dw-apb-uart";
			reg = <0xffc03000 0x00000100>;
			interrupt-parent = <&hps_0_arm_gic_0>;
			interrupts = <0 163 4>;
			clocks = <&l4_sp_clk>;
			reg-io-width = <4>;	/* embeddedsw.dts.params.reg-io-width type NUMBER */
			reg-shift = <2>;	/* embeddedsw.dts.params.reg-shift type NUMBER */
			status = "disabled";	/* embeddedsw.dts.params.status type STRING */
		}; //end serial@ffc03000 (hps_0_uart1)

		hps_0_timer0: timer@ffc08000 {
			compatible = "snps,dw-apb-timer-sp-20.1", "snps,dw-apb-timer-sp";
			reg = <0xffc08000 0x00000100>;
			interrupt-parent = <&hps_0_arm_gic_0>;
			interrupts = <0 167 4>;
			clocks = <&l4_sp_clk>;
			clock-names = "timer";	/* embeddedsw.dts.params.clock-names type STRING */
		}; //end timer@ffc08000 (hps_0_timer0)

		hps_0_timer1: timer@ffc09000 {
			compatible = "snps,dw-apb-timer-sp-20.1", "snps,dw-apb-timer-sp";
			reg = <0xffc09000 0x00000100>;
			interrupt-parent = <&hps_0_arm_gic_0>;
			interrupts = <0 168 4>;
			clocks = <&l4_sp_clk>;
			clock-names = "timer";	/* embeddedsw.dts.params.clock-names type STRING */
		}; //end timer@ffc09000 (hps_0_timer1)

		hps_0_timer2: timer@ffd00000 {
			compatible = "snps,dw-apb-timer-osc-20.1", "snps,dw-apb-timer-osc";
			reg = <0xffd00000 0x00000100>;
			interrupt-parent = <&hps_0_arm_gic_0>;
			interrupts = <0 169 4>;
			clocks = <&hps_0_eosc1>;
			clock-names = "timer";	/* embeddedsw.dts.params.clock-names type STRING */
		}; //end timer@ffd00000 (hps_0_timer2)

		hps_0_timer3: timer@ffd01000 {
			compatible = "snps,dw-apb-timer-osc-20.1", "snps,dw-apb-timer-osc";
			reg = <0xffd01000 0x00000100>;
			interrupt-parent = <&hps_0_arm_gic_0>;
			interrupts = <0 170 4>;
			clocks = <&hps_0_eosc1>;
			clock-names = "timer";	/* embeddedsw.dts.params.clock-names type STRING */
		}; //end timer@ffd01000 (hps_0_timer3)

		hps_0_wd_timer0: timer@ffd02000 {
			compatible = "snps,dw-wdt-20.1", "snps,dw-wdt";
			reg = <0xffd02000 0x00000100>;
			interrupt-parent = <&hps_0_arm_gic_0>;
			interrupts = <0 171 4>;
			clocks = <&hps_0_eosc1>;
			clock-names = "timer";	/* embeddedsw.dts.params.clock-names type STRING */
		}; //end timer@ffd02000 (hps_0_wd_timer0)

		hps_0_wd_timer1: timer@ffd03000 {
			compatible = "snps,dw-wdt-20.1", "snps,dw-wdt";
			reg = <0xffd03000 0x00000100>;
			interrupt-parent = <&hps_0_arm_gic_0>;
			interrupts = <0 172 4>;
			clocks = <&per_base_clk>;
			clock-names = "timer";	/* embeddedsw.dts.params.clock-names type STRING */
			status = "disabled";	/* appended from boardinfo */
		}; //end timer@ffd03000 (hps_0_wd_timer1)

		hps_0_gpio0: gpio@ff708000 {
			compatible = "snps,dw-apb-gpio", "snps,dw-gpio-20.1", "snps,dw-gpio";
			reg = <0xff708000 0x00000100>;
			interrupt-parent = <&hps_0_arm_gic_0>;
			interrupts = <0 164 4>;
			clocks = <&l4_mp_clk>;
			#gpio-cells = <2>;
			gpio-controller;
			#address-cells = <1>;
			#size-cells = <0>;

			hps_0_gpio0_porta: gpio-controller@0 {
				compatible = "snps,dw-apb-gpio-port";
				gpio-controller;
				#gpio-cells = <2>;
				snps,nr-gpios = <29>;	/* appended from boardinfo */
				reg = <0>;
				interrupt-controller;
				#interrupt-cells = <2>;
				interrupts = <0 164 4>;
				interrupt-parent = <&hps_0_arm_gic_0>;
			}; //end gpio-controller@0 (hps_0_gpio0_porta)
		}; //end gpio@ff708000 (hps_0_gpio0)

		hps_0_gpio1: gpio@ff709000 {
			compatible = "snps,dw-apb-gpio", "snps,dw-gpio-20.1", "snps,dw-gpio";
			reg = <0xff709000 0x00000100>;
			interrupt-parent = <&hps_0_arm_gic_0>;
			interrupts = <0 165 4>;
			clocks = <&l4_mp_clk>;
			#gpio-cells = <2>;
			gpio-controller;
			#address-cells = <1>;
			#size-cells = <0>;

			hps_0_gpio1_porta: gpio-controller@0 {
				compatible = "snps,dw-apb-gpio-port";
				gpio-controller;
				#gpio-cells = <2>;
				snps,nr-gpios = <29>;	/* appended from boardinfo */
				reg = <0>;
				interrupt-controller;
				#interrupt-cells = <2>;
				interrupts = <0 165 4>;
				interrupt-parent = <&hps_0_arm_gic_0>;
			}; //end gpio-controller@0 (hps_0_gpio1_porta)
		}; //end gpio@ff709000 (hps_0_gpio1)

		hps_0_gpio2: gpio@ff70a000 {
			compatible = "snps,dw-apb-gpio", "snps,dw-gpio-20.1", "snps,dw-gpio";
			reg = <0xff70a000 0x00000100>;
			interrupt-parent = <&hps_0_arm_gic_0>;
			interrupts = <0 166 4>;
			clocks = <&l4_mp_clk>;
			#gpio-cells = <2>;
			gpio-controller;
			#address-cells = <1>;
			#size-cells = <0>;

			hps_0_gpio2_porta: gpio-controller@0 {
				compatible = "snps,dw-apb-gpio-port";
				gpio-controller;
				#gpio-cells = <2>;
				snps,nr-gpios = <27>;
				reg = <0>;
				interrupt-controller;
				#interrupt-cells = <2>;
				interrupts = <0 166 4>;
				interrupt-parent = <&hps_0_arm_gic_0>;
			}; //end gpio-controller@0 (hps_0_gpio2_porta)
		}; //end gpio@ff70a000 (hps_0_gpio2)

		hps_0_i2c0: i2c@ffc04000 {
			compatible = "snps,designware-i2c-20.1", "snps,designware-i2c";
			reg = <0xffc04000 0x00000100>;
			interrupt-parent = <&hps_0_arm_gic_0>;
			interrupts = <0 158 4>;
			clocks = <&l4_sp_clk>;
			emptyfifo_hold_master = <1>;	/* embeddedsw.dts.params.emptyfifo_hold_master type NUMBER */
			status = "okay";	/* embeddedsw.dts.params.status type STRING */
			#address-cells = <1>;
			#size-cells = <0>;
			speed-mode = <0>;	/* appended from boardinfo */
			clock-frequency = <100000>;	/* appended from boardinfo */
			i2c-sda-falling-time-ns = <5000>;	/* appended from boardinfo */
			i2c-scl-falling-time-ns = <5000>;	/* appended from boardinfo */

			lcd: newhaven,nhd-0216k3z-nsw-bbw@28 {
				compatible = "newhaven,nhd-0216k3z-nsw-bbw";
				reg = <0x00000028>;
				height = <2>;	/* appended from boardinfo */
				width = <16>;	/* appended from boardinfo */
				brightness = <8>;	/* appended from boardinfo */
			}; //end newhaven,nhd-0216k3z-nsw-bbw@28 (lcd)

			eeprom: atmel,24c32@51 {
				compatible = "atmel,24c32";
				reg = <0x00000051>;
				pagesize = <32>;	/* appended from boardinfo */
			}; //end atmel,24c32@51 (eeprom)

			rtc: dallas,ds1339@68 {
				compatible = "dallas,ds1339";
				reg = <0x00000068>;
			}; //end dallas,ds1339@68 (rtc)
			
			adau1761: adau1761@3b {
				compatible = "adi,adau1761";
				reg = <0x3b>;

				clocks = <&adau1761_mclk>;		
				clock-names = "mclk";
			}; //end adi,adau1761@3b (Audio Codec)
			
		}; //end i2c@ffc04000 (hps_0_i2c0)

		hps_0_i2c1: i2c@ffc05000 {
			compatible = "snps,designware-i2c-20.1", "snps,designware-i2c";
			reg = <0xffc05000 0x00000100>;
			interrupt-parent = <&hps_0_arm_gic_0>;
			interrupts = <0 159 4>;
			clocks = <&l4_sp_clk>;
			emptyfifo_hold_master = <1>;	/* embeddedsw.dts.params.emptyfifo_hold_master type NUMBER */
			status = "disabled";	/* embeddedsw.dts.params.status type STRING */
		}; //end i2c@ffc05000 (hps_0_i2c1)

		hps_0_i2c2: i2c@ffc06000 {
			compatible = "snps,designware-i2c-20.1", "snps,designware-i2c";
			reg = <0xffc06000 0x00000100>;
			interrupt-parent = <&hps_0_arm_gic_0>;
			interrupts = <0 160 4>;
			clocks = <&l4_sp_clk>;
			emptyfifo_hold_master = <1>;	/* embeddedsw.dts.params.emptyfifo_hold_master type NUMBER */
			status = "disabled";	/* embeddedsw.dts.params.status type STRING */
		}; //end i2c@ffc06000 (hps_0_i2c2)

		hps_0_i2c3: i2c@ffc07000 {
			compatible = "snps,designware-i2c-20.1", "snps,designware-i2c";
			reg = <0xffc07000 0x00000100>;
			interrupt-parent = <&hps_0_arm_gic_0>;
			interrupts = <0 161 4>;
			clocks = <&l4_sp_clk>;
			emptyfifo_hold_master = <1>;	/* embeddedsw.dts.params.emptyfifo_hold_master type NUMBER */
			status = "disabled";	/* embeddedsw.dts.params.status type STRING */
		}; //end i2c@ffc07000 (hps_0_i2c3)

		hps_0_nand0: flash@ff900000 {
			compatible = "denali,nand-20.1", "denali,denali-nand-dt";
			reg = <0xff900000 0x00010000>,
				<0xffb80000 0x00010000>;
			reg-names = "nand_data", "denali_reg";	/* embeddedsw.dts.params.reg-names type STRING */
			interrupt-parent = <&hps_0_arm_gic_0>;
			interrupts = <0 144 4>;
			clocks = <&nand_clk>;
			#address-cells = <1>;	/* embeddedsw.dts.params.#address-cells type NUMBER */
			#size-cells = <1>;	/* embeddedsw.dts.params.#size-cells type NUMBER */
			status = "disabled";	/* embeddedsw.dts.params.status type STRING */
			bank-width = <2>;
			device-width = <1>;
		}; //end flash@ff900000 (hps_0_nand0)

		hps_0_spim0: spi@fff00000 {
			compatible = "snps,dw-spi-mmio-20.1", "snps,dw-spi-mmio", "snps,dw-apb-ssi";
			reg = <0xfff00000 0x00000100>;
			interrupt-parent = <&hps_0_arm_gic_0>;
			interrupts = <0 154 4>;
			clocks = <&spi_m_clk>;
			#address-cells = <1>;	/* embeddedsw.dts.params.#address-cells type NUMBER */
			#size-cells = <0>;	/* embeddedsw.dts.params.#size-cells type NUMBER */
			bus-num = <0>;	/* embeddedsw.dts.params.bus-num type NUMBER */
			num-chipselect = <4>;	/* embeddedsw.dts.params.num-chipselect type NUMBER */
			status = "disabled";	/* embeddedsw.dts.params.status type STRING */

			spidev0: spidev@0 {
				compatible = "rohm,dh2228fv";	/* appended from boardinfo */
				reg = <0>;	/* appended from boardinfo */
				spi-max-frequency = <100000000>;	/* appended from boardinfo */
				enable-dma = <1>;	/* appended from boardinfo */
			}; //end spidev@0 (spidev0)
		}; //end spi@fff00000 (hps_0_spim0)

		hps_0_spim1: spi@fff01000 {
			compatible = "snps,dw-spi-mmio-20.1", "snps,dw-spi-mmio", "snps,dw-apb-ssi";
			reg = <0xfff01000 0x00000100>;
			interrupt-parent = <&hps_0_arm_gic_0>;
			interrupts = <0 155 4>;
			clocks = <&spi_m_clk>;
			#address-cells = <1>;	/* embeddedsw.dts.params.#address-cells type NUMBER */
			#size-cells = <0>;	/* embeddedsw.dts.params.#size-cells type NUMBER */
			bus-num = <0>;	/* embeddedsw.dts.params.bus-num type NUMBER */
			num-chipselect = <4>;	/* embeddedsw.dts.params.num-chipselect type NUMBER */
			status = "disabled";	/* embeddedsw.dts.params.status type STRING */
		}; //end spi@fff01000 (hps_0_spim1)

		hps_0_qspi: flash@ff705000 {
			compatible = "cadence,qspi-20.1", "cadence,qspi", "cdns,qspi-nor";
			reg = <0xff705000 0x00000100>,
				<0xffa00000 0x00000100>;
			reg-names = "axi_slave0", "axi_slave1";
			interrupt-parent = <&hps_0_arm_gic_0>;
			interrupts = <0 151 4>;
			clocks = <&qspi_clk>;
			bus-num = <2>;	/* embeddedsw.dts.params.bus-num type NUMBER */
			fifo-depth = <128>;	/* embeddedsw.dts.params.fifo-depth type NUMBER */
			num-chipselect = <4>;	/* embeddedsw.dts.params.num-chipselect type NUMBER */
			status = "okay";	/* embeddedsw.dts.params.status type STRING */
			bank-width = <2>;
			device-width = <1>;
			#address-cells = <1>;	/* appended from boardinfo */
			#size-cells = <0>;	/* appended from boardinfo */
			master-ref-clk = <400000000>;	/* appended from boardinfo */
			ext-decoder = <0>;	/* appended from boardinfo */

			flash0: n25q512a@0 {
				compatible = "n25q512a";	/* appended from boardinfo */
				#address-cells = <1>;	/* appended from boardinfo */
				#size-cells = <1>;	/* appended from boardinfo */
				reg = <0>;	/* appended from boardinfo */
				spi-max-frequency = <100000000>;	/* appended from boardinfo */
				m25p,fast-read;	/* appended from boardinfo */
				page-size = <256>;	/* appended from boardinfo */
				block-size = <16>;	/* appended from boardinfo */
				tshsl-ns = <50>;	/* appended from boardinfo */
				tsd2d-ns = <50>;	/* appended from boardinfo */
				tchsh-ns = <4>;	/* appended from boardinfo */
				tslch-ns = <4>;	/* appended from boardinfo */
				cdns,page-size = <256>;	/* appended from boardinfo */
				cdns,block-size = <16>;	/* appended from boardinfo */
				cdns,tshsl-ns = <50>;	/* appended from boardinfo */
				cdns,tsd2d-ns = <50>;	/* appended from boardinfo */
				cdns,tchsh-ns = <4>;	/* appended from boardinfo */
				cdns,tslch-ns = <4>;	/* appended from boardinfo */

				part0: partition@0 {
					label = "Flash 0 Raw Data";	/* appended from boardinfo */
					reg = <0x00000000 0x00800000>;	/* appended from boardinfo */
				}; //end partition@0 (part0)

				part1: partition@800000 {
					label = "Flash 1 jffs2 Filesystem";	/* appended from boardinfo */
					reg = <0x00800000 0x03800000>;	/* appended from boardinfo */
				}; //end partition@800000 (part1)
			}; //end n25q512a@0 (flash0)
		}; //end flash@ff705000 (hps_0_qspi)

		hps_0_sdmmc: flash@ff704000 {
			compatible = "altr,socfpga-dw-mshc";	/* appended from boardinfo */
			reg = <0xff704000 0x00001000>;
			interrupt-parent = <&hps_0_arm_gic_0>;
			interrupts = <0 139 4>;
			clocks = <&l4_mp_clk &sdmmc_clk_divided>;	/* appended from boardinfo */
			clock-names = "biu", "ciu";
			fifo-depth = <1024>;	/* embeddedsw.dts.params.fifo-depth type NUMBER */
			num-slots = <1>;	/* embeddedsw.dts.params.num-slots type NUMBER */
			status = "okay";	/* embeddedsw.dts.params.status type STRING */
			#address-cells = <1>;	/* appended from boardinfo */
			#size-cells = <0>;	/* appended from boardinfo */
			broken-cd;	/* appended from boardinfo */
			cap-mmc-highspeed;	/* appended from boardinfo */
			cap-sd-highspeed;	/* appended from boardinfo */
			bus-width = <4>;	/* appended from boardinfo */
			altr,dw-mshc-ciu-div = <3>;	/* appended from boardinfo */
			altr,dw-mshc-sdr-timing = <0 3>;	/* appended from boardinfo */
			supports-highspeed;	/* appended from boardinfo */
			cd = <&hps_0_gpio1_porta 18 0>;	/* appended from boardinfo */
			cd-gpios = <&hps_0_gpio1_porta 18 0>;	/* appended from boardinfo */
			vmmc-supply = <&regulator_3_3v>;	/* appended from boardinfo */
			vqmmc-supply = <&regulator_3_3v>;	/* appended from boardinfo */

			slot_0: slot@0 {
				reg = <0>;	/* appended from boardinfo */
				bus-width = <4>;	/* appended from boardinfo */
			}; //end slot@0 (slot_0)
		}; //end flash@ff704000 (hps_0_sdmmc)

		hps_0_usb0: usb@ffb00000 {
			compatible = "snps,dwc-otg-20.1", "snps,dwc-otg", "snps,dwc2";
			reg = <0xffb00000 0x00040000>;
			interrupt-parent = <&hps_0_arm_gic_0>;
			interrupts = <0 125 4>;
			clocks = <&usb_mp_clk>;
			clock-names = "otg";	/* embeddedsw.dts.params.clock-names type STRING */
			dev-nperio-tx-fifo-size = <4096>;	/* embeddedsw.dts.params.dev-nperio-tx-fifo-size type NUMBER */
			dev-perio-tx-fifo-size = "<512 512 512 512 512 512 512 512 512 512 512 512 512 512 512>";	/* embeddedsw.dts.params.dev-perio-tx-fifo-size type STRING */
			dev-rx-fifo-size = <512>;	/* embeddedsw.dts.params.dev-rx-fifo-size type NUMBER */
			dev-tx-fifo-size = "<512 512 512 512 512 512 512 512 512 512 512 512 512 512 512>";	/* embeddedsw.dts.params.dev-tx-fifo-size type STRING */
			dma-mask = <268435455>;	/* embeddedsw.dts.params.dma-mask type NUMBER */
			enable-dynamic-fifo = <1>;	/* embeddedsw.dts.params.enable-dynamic-fifo type NUMBER */
			host-nperio-tx-fifo-size = <2560>;	/* embeddedsw.dts.params.host-nperio-tx-fifo-size type NUMBER */
			host-perio-tx-fifo-size = <2560>;	/* embeddedsw.dts.params.host-perio-tx-fifo-size type NUMBER */
			host-rx-fifo-size = <2560>;	/* embeddedsw.dts.params.host-rx-fifo-size type NUMBER */
			phy-names = "usb2-phy";	/* embeddedsw.dts.params.phy-names type STRING */
			status = "disabled";	/* embeddedsw.dts.params.status type STRING */
			ulpi-ddr = <0>;	/* embeddedsw.dts.params.ulpi-ddr type NUMBER */
			voltage-switch = <0>;	/* embeddedsw.dts.params.voltage-switch type NUMBER */
		}; //end usb@ffb00000 (hps_0_usb0)

		hps_0_usb1: usb@ffb40000 {
			compatible = "snps,dwc-otg-20.1", "snps,dwc-otg", "snps,dwc2";
			reg = <0xffb40000 0x00040000>;
			interrupt-parent = <&hps_0_arm_gic_0>;
			interrupts = <0 128 4>;
			clocks = <&usb_mp_clk>;
			clock-names = "otg";	/* embeddedsw.dts.params.clock-names type STRING */
			dev-nperio-tx-fifo-size = <4096>;	/* embeddedsw.dts.params.dev-nperio-tx-fifo-size type NUMBER */
			dev-perio-tx-fifo-size = "<512 512 512 512 512 512 512 512 512 512 512 512 512 512 512>";	/* embeddedsw.dts.params.dev-perio-tx-fifo-size type STRING */
			dev-rx-fifo-size = <512>;	/* embeddedsw.dts.params.dev-rx-fifo-size type NUMBER */
			dev-tx-fifo-size = "<512 512 512 512 512 512 512 512 512 512 512 512 512 512 512>";	/* embeddedsw.dts.params.dev-tx-fifo-size type STRING */
			dma-mask = <268435455>;	/* embeddedsw.dts.params.dma-mask type NUMBER */
			enable-dynamic-fifo = <1>;	/* embeddedsw.dts.params.enable-dynamic-fifo type NUMBER */
			host-nperio-tx-fifo-size = <2560>;	/* embeddedsw.dts.params.host-nperio-tx-fifo-size type NUMBER */
			host-perio-tx-fifo-size = <2560>;	/* embeddedsw.dts.params.host-perio-tx-fifo-size type NUMBER */
			host-rx-fifo-size = <2560>;	/* embeddedsw.dts.params.host-rx-fifo-size type NUMBER */
			phy-names = "usb2-phy";	/* embeddedsw.dts.params.phy-names type STRING */
			status = "okay";	/* embeddedsw.dts.params.status type STRING */
			ulpi-ddr = <0>;	/* embeddedsw.dts.params.ulpi-ddr type NUMBER */
			voltage-switch = <0>;	/* embeddedsw.dts.params.voltage-switch type NUMBER */
			phys = <&usbphy0>;	/* appended from boardinfo */
		}; //end usb@ffb40000 (hps_0_usb1)

		hps_0_gmac0: ethernet@ff700000 {
			compatible = "synopsys,dwmac-20.1", "altr,socfpga-stmmac", "snps,dwmac-3.70a", "snps,dwmac";
			reg = <0xff700000 0x00002000>;
			interrupt-parent = <&hps_0_arm_gic_0>;
			interrupts = <0 115 4>;
			clocks = <&emac0_clk>;
			clock-names = "stmmaceth";	/* embeddedsw.dts.params.clock-names type STRING */
			interrupt-names = "macirq";	/* embeddedsw.dts.params.interrupt-names type STRING */
			rx-fifo-depth = <4096>;	/* embeddedsw.dts.params.rx-fifo-depth type NUMBER */
			snps,multicast-filter-bins = <256>;	/* embeddedsw.dts.params.snps,multicast-filter-bins type NUMBER */
			snps,perfect-filter-entries = <128>;	/* embeddedsw.dts.params.snps,perfect-filter-entries type NUMBER */
			status = "disabled";	/* embeddedsw.dts.params.status type STRING */
			tx-fifo-depth = <4096>;	/* embeddedsw.dts.params.tx-fifo-depth type NUMBER */
			address-bits = <48>;
			max-frame-size = <1518>;
			local-mac-address = [00 00 00 00 00 00];
			reset-names = "stmmaceth";	/* appended from boardinfo */
			resets = <&hps_0_rstmgr 32>;	/* appended from boardinfo */
		}; //end ethernet@ff700000 (hps_0_gmac0)

		hps_0_gmac1: ethernet@ff702000 {
			compatible = "synopsys,dwmac-20.1", "altr,socfpga-stmmac", "snps,dwmac-3.70a", "snps,dwmac";
			reg = <0xff702000 0x00002000>;
			interrupt-parent = <&hps_0_arm_gic_0>;
			interrupts = <0 120 4>;
			clocks = <&emac1_clk>;
			clock-names = "stmmaceth";	/* embeddedsw.dts.params.clock-names type STRING */
			interrupt-names = "macirq";	/* embeddedsw.dts.params.interrupt-names type STRING */
			rx-fifo-depth = <4096>;	/* embeddedsw.dts.params.rx-fifo-depth type NUMBER */
			snps,multicast-filter-bins = <256>;	/* embeddedsw.dts.params.snps,multicast-filter-bins type NUMBER */
			snps,perfect-filter-entries = <128>;	/* embeddedsw.dts.params.snps,perfect-filter-entries type NUMBER */
			status = "disabled";	/* embeddedsw.dts.params.status type STRING */
			tx-fifo-depth = <4096>;	/* embeddedsw.dts.params.tx-fifo-depth type NUMBER */
			address-bits = <48>;
			max-frame-size = <3800>;	/* appended from boardinfo */
			local-mac-address = [00 00 00 00 00 00];
			phy-mode = "rgmii";	/* appended from boardinfo */
			snps,phy-addr = <0xffffffff>;	/* appended from boardinfo */
			phy-addr = <0xffffffff>;	/* appended from boardinfo */
			txc-skew-ps = <3000>;	/* appended from boardinfo */
			rxc-skew-ps = <3000>;	/* appended from boardinfo */
			txen-skew-ps = <0>;	/* appended from boardinfo */
			rxdv-skew-ps = <0>;	/* appended from boardinfo */
			rxd0-skew-ps = <0>;	/* appended from boardinfo */
			rxd1-skew-ps = <0>;	/* appended from boardinfo */
			rxd2-skew-ps = <0>;	/* appended from boardinfo */
			rxd3-skew-ps = <0>;	/* appended from boardinfo */
			txd0-skew-ps = <0>;	/* appended from boardinfo */
			txd1-skew-ps = <0>;	/* appended from boardinfo */
			txd2-skew-ps = <0>;	/* appended from boardinfo */
			txd3-skew-ps = <0>;	/* appended from boardinfo */
			altr,sysmgr-syscon = <&hps_0_sysmgr 0x00000060 2>;	/* appended from boardinfo */
			reset-names = "stmmaceth";	/* appended from boardinfo */
			resets = <&hps_0_rstmgr 33>;	/* appended from boardinfo */
		}; //end ethernet@ff702000 (hps_0_gmac1)

		hps_0_dcan0: can@ffc00000 {
			compatible = "bosch,dcan-20.1", "bosch,d_can";
			reg = <0xffc00000 0x00001000>;
			interrupt-parent = <&hps_0_arm_gic_0>;
			interrupts = <0 131 4 0 132 4>;
			interrupt-names = "interrupt_sender0", "interrupt_sender1";
			clocks = <&can0_clk>;
			status = "disabled";	/* embeddedsw.dts.params.status type STRING */
		}; //end can@ffc00000 (hps_0_dcan0)

		hps_0_dcan1: can@ffc01000 {
			compatible = "bosch,dcan-20.1", "bosch,d_can";
			reg = <0xffc01000 0x00001000>;
			interrupt-parent = <&hps_0_arm_gic_0>;
			interrupts = <0 135 4 0 136 4>;
			interrupt-names = "interrupt_sender0", "interrupt_sender1";
			clocks = <&can1_clk>;
			status = "disabled";	/* embeddedsw.dts.params.status type STRING */
		}; //end can@ffc01000 (hps_0_dcan1)

		hps_0_l3regs: rl3regs@ff800000 {
			compatible = "altr,l3regs-20.1", "altr,l3regs", "syscon";
			reg = <0xff800000 0x00001000>;
		}; //end rl3regs@ff800000 (hps_0_l3regs)

		hps_0_sdrctl: sdr-ctl@ffc25000 {
			compatible = "altr,sdr-ctl-20.1", "altr,sdr-ctl", "syscon";
			reg = <0xffc25000 0x00001000>;
		}; //end sdr-ctl@ffc25000 (hps_0_sdrctl)

		hps_0_timer: timer@fffec600 {
			compatible = "arm,cortex-a9-twd-timer-20.1", "arm,cortex-a9-twd-timer";
			reg = <0xfffec600 0x00000100>;
			interrupt-parent = <&hps_0_arm_gic_0>;
			interrupts = <1 13 0xf01>;  // interrupts = <1 13 3844>; https://www.mail-archive.com/linux-kernel@vger.kernel.org/msg1646131.html
			clocks = <&mpu_periph_clk>;
		}; //end timer@fffec600 (hps_0_timer)

		hps_0_scu: scu@fffec000 {
			compatible = "arm,corex-a9-scu-20.1", "arm,cortex-a9-scu";
			reg = <0xfffec000 0x00000100>;
		}; //end scu@fffec000 (hps_0_scu)

		regulator_3_3v: vcc3p3-regulator {
			compatible = "regulator-fixed";	/* appended from boardinfo */
			regulator-name = "3.3V";	/* appended from boardinfo */
			regulator-min-microvolt = <3300000>;	/* appended from boardinfo */
			regulator-max-microvolt = <3300000>;	/* appended from boardinfo */
		}; //end vcc3p3-regulator (regulator_3_3v)

		soc_leds: leds {
			compatible = "gpio-leds";	/* appended from boardinfo */

			led_hps0: hps0 {
				label = "hps_led0";	/* appended from boardinfo */
				gpios = <&hps_0_gpio1_porta 15 1>;	/* appended from boardinfo */
			}; //end hps0 (led_hps0)
		}; //end leds (soc_leds)

		pmu: pmu0 {
			#address-cells = <1>;	/* appended from boardinfo */
			#size-cells = <1>;	/* appended from boardinfo */
			compatible = "arm,cortex-a9-pmu";	/* appended from boardinfo */
			interrupt-parent = <&hps_0_arm_gic_0>;	/* appended from boardinfo */
			interrupts = <0 176 4 0 177 4>;	/* appended from boardinfo */
			ranges;	/* appended from boardinfo */

			cti0: cti0@ff118000 {
				compatible = "arm,coresight-cti";	/* appended from boardinfo */
				reg = <0xff118000 0x00001000>;	/* appended from boardinfo */
			}; //end cti0@ff118000 (cti0)

			cti1: cti0@ff119000 {
				compatible = "arm,coresight-cti";	/* appended from boardinfo */
				reg = <0xff119000 0x00001000>;	/* appended from boardinfo */
			}; //end cti0@ff119000 (cti1)
		}; //end pmu0 (pmu)

		fpgabridge0: fpgabridge@ff500000 {
			compatible = "altr,socfpga-hps2fpga-bridge";	/* appended from boardinfo */
			reg = <0xff500000 0x10000>;
			label = "hps2fpga";	/* appended from boardinfo */
			reset-names = "hps2fpga";	/* appended from boardinfo */
			clocks = <&l4_main_clk>;	/* appended from boardinfo */
			resets = <&hps_0_rstmgr 96>;	/* appended from boardinfo */
		}; //end fpgabridge@0 (fpgabridge0)

		fpgabridge1: fpgabridge@ff400000 {
			compatible = "altr,socfpga-lwhps2fpga-bridge";	/* appended from boardinfo */
			reg = <0xff400000 0x100000>;
			label = "lwhps2fpga";	/* appended from boardinfo */
			reset-names = "lwhps2fpga";	/* appended from boardinfo */
			clocks = <&l4_main_clk>;	/* appended from boardinfo */
			resets = <&hps_0_rstmgr 97>;	/* appended from boardinfo */
		}; //end fpgabridge@1 (fpgabridge1)

		fpgabridge2: fpgabridge@ff600000 {
			compatible = "altr,socfpga-fpga2hps-bridge";	/* appended from boardinfo */
			reg = <0xff600000 0x100000>;
			label = "fpga2hps";	/* appended from boardinfo */
			reset-names = "fpga2hps";	/* appended from boardinfo */
			clocks = <&l4_main_clk>;	/* appended from boardinfo */
			resets = <&hps_0_rstmgr 98>;	/* appended from boardinfo */
		}; //end fpgabridge@2 (fpgabridge2)

		fpgabridge3: fpgabridge@ffc25080 {
			compatible = "altr,socfpga-fpga2sdram-bridge";	/* appended from boardinfo */
			reg = <0xffc25080 0x4>;
			label = "fpga2sdram";	/* appended from boardinfo */
			read-ports-mask = <0x0000000f>;	/* appended from boardinfo */
			write-ports-mask = <0x0000000f>;	/* appended from boardinfo */
			cmd-ports-mask = <0x00000001>;	/* appended from boardinfo */
		}; //end fpgabridge@3 (fpgabridge3)

		usbphy0: usbphy {
			#phy-cells = <0>;	/* appended from boardinfo */
			compatible = "usb-nop-xceiv";	/* appended from boardinfo */
			status = "okay";	/* appended from boardinfo */
		}; //end usbphy@0 (usbphy0)
	}; //end sopc@0 (sopc0)

	chosen {
		bootargs = "earlyprintk";  // bootargs = "console=ttyS0,115200";
		stdout-path = "serial0:115200n8";
	}; //end chosen
}; //end /
